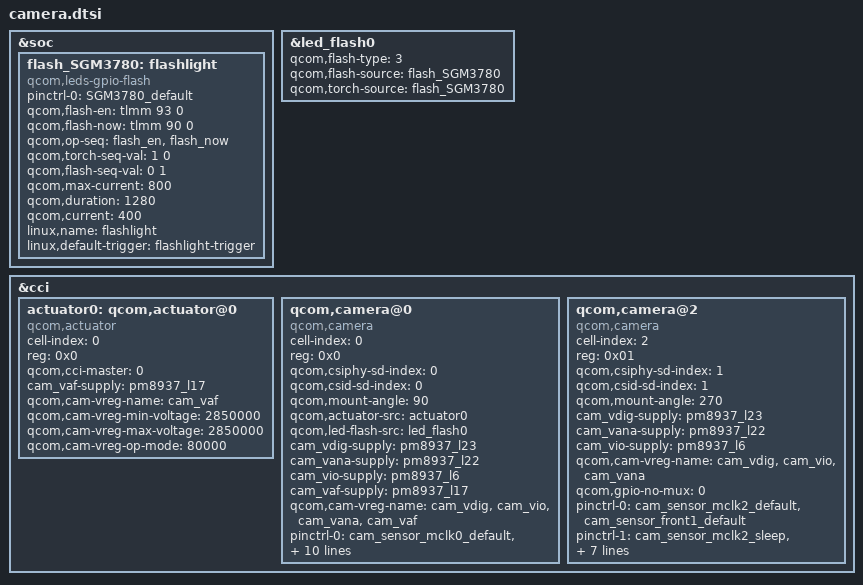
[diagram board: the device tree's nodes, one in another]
/* From stock msm8917-camera-sensor-qrd-s8850?.dtsi */
&soc {
	flash_SGM3780:flashlight {
		compatible = "qcom,leds-gpio-flash";
		status = "okay";
		pinctrl-names = "flash_default";
		pinctrl-0 = <&SGM3780_default>;
		qcom,flash-en = <&tlmm 93 0>;
		qcom,flash-now = <&tlmm 90 0>;
		qcom,op-seq = "flash_en", "flash_now";
		qcom,torch-seq-val = <1 0>;
		qcom,flash-seq-val = <0 1>;
		qcom,max-current = <800>;
		qcom,duration = <1280>;
		qcom,current = <400>;
		linux,name = "flashlight";
		linux,default-trigger = "flashlight-trigger";
	};
};
&led_flash0 {
	qcom,flash-type = <3>;
	qcom,flash-source = <&flash_SGM3780>;
	qcom,torch-source = <&flash_SGM3780>;
};
&cci {
	actuator0: qcom,actuator@0 {
		cell-index = <0>;
		reg = <0x0>;
		compatible = "qcom,actuator";
		qcom,cci-master = <0>;
		cam_vaf-supply = <&pm8937_l17>;
		qcom,cam-vreg-name = "cam_vaf";
		qcom,cam-vreg-min-voltage = <2850000>;
		qcom,cam-vreg-max-voltage = <2850000>;
		qcom,cam-vreg-op-mode = <80000>;
	};
	qcom,camera@0 {
		cell-index = <0>;
		compatible = "qcom,camera";
		reg = <0x0>;
		qcom,csiphy-sd-index = <0>;
		qcom,csid-sd-index = <0>;
		qcom,mount-angle = <90>;
		qcom,actuator-src = <&actuator0>;
		qcom,led-flash-src = <&led_flash0>;
		cam_vdig-supply = <&pm8937_l23>;
		cam_vana-supply = <&pm8937_l22>;
		cam_vio-supply = <&pm8937_l6>;
		cam_vaf-supply = <&pm8937_l17>;
		qcom,cam-vreg-name = "cam_vdig", "cam_vio", "cam_vana",
							"cam_vaf";
		pinctrl-names = "cam_default", "cam_suspend";
		pinctrl-0 = <&cam_sensor_mclk0_default
				&cam_sensor_rear_default>;
		pinctrl-1 = <&cam_sensor_mclk0_sleep
				&cam_sensor_rear_sleep>;
		qcom,gpio-reset = <1>;
		qcom,sensor-position = <0>;
		qcom,sensor-mode = <0>;
		qcom,cci-master = <0>;
		clocks = <&gcc MCLK0_CLK_SRC>,
			<&gcc GCC_CAMSS_MCLK0_CLK>;
		clock-names = "cam_src_clk", "cam_clk";
		qcom,clock-rates = <24000000 0>;
	};
	qcom,camera@2 {
		cell-index = <2>;
		compatible = "qcom,camera";
		reg = <0x01>;
		qcom,csiphy-sd-index = <1>;
		qcom,csid-sd-index = <1>;
		qcom,mount-angle = <270>;
		cam_vdig-supply = <&pm8937_l23>;
		cam_vana-supply = <&pm8937_l22>;
		cam_vio-supply = <&pm8937_l6>;
		qcom,cam-vreg-name = "cam_vdig", "cam_vio", "cam_vana";
		qcom,gpio-no-mux = <0>;
		pinctrl-names = "cam_default", "cam_suspend";
		pinctrl-0 = <&cam_sensor_mclk2_default
				&cam_sensor_front1_default>;
		pinctrl-1 = <&cam_sensor_mclk2_sleep
				&cam_sensor_front1_sleep>;
		qcom,sensor-position = <1>;
		qcom,sensor-mode = <0>;
		qcom,cci-master = <0>;
		clocks = <&gcc MCLK2_CLK_SRC>,
			<&gcc GCC_CAMSS_MCLK2_CLK>;
		clock-names = "cam_src_clk", "cam_clk";
		qcom,clock-rates = <24000000 0>;
	};
};
